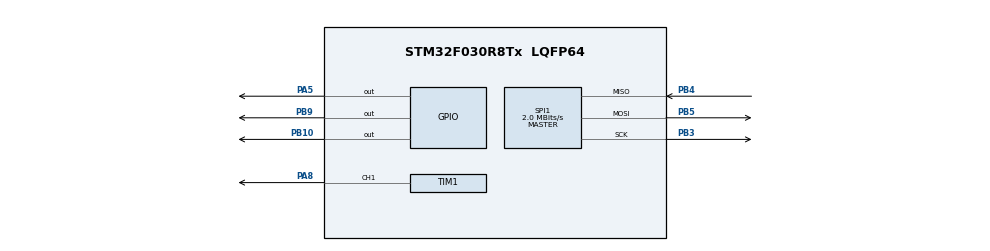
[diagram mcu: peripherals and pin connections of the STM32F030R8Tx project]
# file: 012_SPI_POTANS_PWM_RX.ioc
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Mcu.Family=STM32F0
Mcu.Name=STM32F030R8Tx
Mcu.Package=LQFP64
PA13.Mode=Serial_Wire
PA13.Signal=SYS_SWDIO
PA14.Mode=Serial_Wire
PA14.Signal=SYS_SWCLK
PA5.Signal=GPIO_Output
PA8.Signal=S_TIM1_CH1
PB10.GPIO_Speed=GPIO_SPEED_FREQ_HIGH
PB10.PinState=GPIO_PIN_RESET
PB10.Signal=GPIO_Output
PB3.Mode=Full_Duplex_Master
PB3.Signal=SPI1_SCK
PB4.Mode=Full_Duplex_Master
PB4.Signal=SPI1_MISO
PB5.Mode=Full_Duplex_Master
PB5.Signal=SPI1_MOSI
PB9.GPIO_Speed=GPIO_SPEED_FREQ_HIGH
PB9.Signal=GPIO_Output
ProjectManager.HeapSize=0x200
ProjectManager.StackSize=0x400
ProjectManager.TargetToolchain=STM32CubeIDE
SH.S_TIM1_CH1.0=TIM1_CH1,PWM Generation1 CH1
SPI1.BaudRatePrescaler=SPI_BAUDRATEPRESCALER_4
SPI1.CalculateBaudRate=2.0 MBits/s
SPI1.DataSize=SPI_DATASIZE_8BIT
SPI1.Direction=SPI_DIRECTION_2LINES
SPI1.Mode=SPI_MODE_MASTER
SPI1.VirtualType=VM_MASTER
TIM1.Channel-PWM\ Generation1\ CH1=TIM_CHANNEL_1
TIM1.Period=255
TIM1.Prescaler=8-1
VP_TIM1_VS_ClockSourceINT.Mode=Internal
board=custom

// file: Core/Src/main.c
/* USER CODE BEGIN Header */
/**
  ******************************************************************************
  * @file           : main.c
  * @brief          : Main program body
  ******************************************************************************
  * @attention
  *
  * Copyright (c) 2025 STMicroelectronics.
  * All rights reserved.
  *
  * This software is licensed under terms that can be found in the LICENSE file
  * in the root directory of this software component.
  * If no LICENSE file comes with this software, it is provided AS-IS.
  *
  ******************************************************************************
  */
/* USER CODE END Header */
#include "main.h"

/* USER CODE BEGIN Includes */
#include "nrf24l01.h"
#include "string.h"

/* USER CODE END Includes */

SPI_HandleTypeDef hspi1;

TIM_HandleTypeDef htim1;

/* USER CODE BEGIN PV */
uint8_t rx_address[5] = {0xD1, 0xC2, 0xC3, 0xC4, 0xC5}; // Özel bir adres
uint8_t rx_data[1]; // Gelen veri icin buffer
/* USER CODE END PV */

void SystemClock_Config(void);
static void MX_GPIO_Init(void);
static void MX_SPI1_Init(void);
static void MX_TIM1_Init(void);

int main(void)
{

  /* MCU Configuration--------------------------------------------------------*/

  /* Reset of all peripherals, Initializes the Flash interface and the Systick. */
  HAL_Init();

  /* Configure the system clock */
  SystemClock_Config();

  /* Initialize all configured peripherals */
  MX_GPIO_Init();
  MX_SPI1_Init();
  MX_TIM1_Init();
  /* USER CODE BEGIN 2 */
  	  nrf24_config(40, 1);
      nrf24_rx_address(rx_address);
      nrf24_rx_mode();
      HAL_TIM_PWM_Start(&htim1, TIM_CHANNEL_1);
  /* USER CODE END 2 */

  /* Infinite loop */
  while (1)
  {

    /* USER CODE BEGIN 3 */

	   if (nrf24_dataReady()) // Veri var mı?
	        {
	            nrf24_getData((uint8_t*)rx_data, 1); // Gelen veriyi al
	            __HAL_TIM_SET_COMPARE(&htim1, TIM_CHANNEL_1, rx_data[0]);
	            HAL_GPIO_TogglePin(GPIOA, GPIO_PIN_5);
	             HAL_Delay(50);
	        }
  }
  /* USER CODE END 3 */
}

void SystemClock_Config(void)
{
  RCC_OscInitTypeDef RCC_OscInitStruct = {0};
  RCC_ClkInitTypeDef RCC_ClkInitStruct = {0};

  /** Initializes the RCC Oscillators according to the specified parameters
  * in the RCC_OscInitTypeDef structure.
  */
  RCC_OscInitStruct.OscillatorType = RCC_OSCILLATORTYPE_HSI;
  RCC_OscInitStruct.HSIState = RCC_HSI_ON;
  RCC_OscInitStruct.HSICalibrationValue = RCC_HSICALIBRATION_DEFAULT;
  RCC_OscInitStruct.PLL.PLLState = RCC_PLL_NONE;
  if (HAL_RCC_OscConfig(&RCC_OscInitStruct) != HAL_OK)
  {
    Error_Handler();
  }

  /** Initializes the CPU, AHB and APB buses clocks
  */
  RCC_ClkInitStruct.ClockType = RCC_CLOCKTYPE_HCLK|RCC_CLOCKTYPE_SYSCLK
                              |RCC_CLOCKTYPE_PCLK1;
  RCC_ClkInitStruct.SYSCLKSource = RCC_SYSCLKSOURCE_HSI;
  RCC_ClkInitStruct.AHBCLKDivider = RCC_SYSCLK_DIV1;
  RCC_ClkInitStruct.APB1CLKDivider = RCC_HCLK_DIV1;

  if (HAL_RCC_ClockConfig(&RCC_ClkInitStruct, FLASH_LATENCY_0) != HAL_OK)
  {
    Error_Handler();
  }
}

static void MX_SPI1_Init(void)
{

  /* SPI1 parameter configuration*/
  hspi1.Instance = SPI1;
  hspi1.Init.Mode = SPI_MODE_MASTER;
  hspi1.Init.Direction = SPI_DIRECTION_2LINES;
  hspi1.Init.DataSize = SPI_DATASIZE_8BIT;
  hspi1.Init.CLKPolarity = SPI_POLARITY_LOW;
  hspi1.Init.CLKPhase = SPI_PHASE_1EDGE;
  hspi1.Init.NSS = SPI_NSS_SOFT;
  hspi1.Init.BaudRatePrescaler = SPI_BAUDRATEPRESCALER_4;
  hspi1.Init.FirstBit = SPI_FIRSTBIT_MSB;
  hspi1.Init.TIMode = SPI_TIMODE_DISABLE;
  hspi1.Init.CRCCalculation = SPI_CRCCALCULATION_DISABLE;
  hspi1.Init.CRCPolynomial = 7;
  hspi1.Init.CRCLength = SPI_CRC_LENGTH_DATASIZE;
  hspi1.Init.NSSPMode = SPI_NSS_PULSE_ENABLE;
  if (HAL_SPI_Init(&hspi1) != HAL_OK)
  {
    Error_Handler();
  }

}

static void MX_TIM1_Init(void)
{

  TIM_ClockConfigTypeDef sClockSourceConfig = {0};
  TIM_MasterConfigTypeDef sMasterConfig = {0};
  TIM_OC_InitTypeDef sConfigOC = {0};
  TIM_BreakDeadTimeConfigTypeDef sBreakDeadTimeConfig = {0};

  htim1.Instance = TIM1;
  htim1.Init.Prescaler = 8-1;
  htim1.Init.CounterMode = TIM_COUNTERMODE_UP;
  htim1.Init.Period = 255;
  htim1.Init.ClockDivision = TIM_CLOCKDIVISION_DIV1;
  htim1.Init.RepetitionCounter = 0;
  htim1.Init.AutoReloadPreload = TIM_AUTORELOAD_PRELOAD_DISABLE;
  if (HAL_TIM_Base_Init(&htim1) != HAL_OK)
  {
    Error_Handler();
  }
  sClockSourceConfig.ClockSource = TIM_CLOCKSOURCE_INTERNAL;
  if (HAL_TIM_ConfigClockSource(&htim1, &sClockSourceConfig) != HAL_OK)
  {
    Error_Handler();
  }
  if (HAL_TIM_PWM_Init(&htim1) != HAL_OK)
  {
    Error_Handler();
  }
  sMasterConfig.MasterOutputTrigger = TIM_TRGO_RESET;
  sMasterConfig.MasterSlaveMode = TIM_MASTERSLAVEMODE_DISABLE;
  if (HAL_TIMEx_MasterConfigSynchronization(&htim1, &sMasterConfig) != HAL_OK)
  {
    Error_Handler();
  }
  sConfigOC.OCMode = TIM_OCMODE_PWM1;
  sConfigOC.Pulse = 0;
  sConfigOC.OCPolarity = TIM_OCPOLARITY_HIGH;
  sConfigOC.OCNPolarity = TIM_OCNPOLARITY_HIGH;
  sConfigOC.OCFastMode = TIM_OCFAST_DISABLE;
  sConfigOC.OCIdleState = TIM_OCIDLESTATE_RESET;
  sConfigOC.OCNIdleState = TIM_OCNIDLESTATE_RESET;
  if (HAL_TIM_PWM_ConfigChannel(&htim1, &sConfigOC, TIM_CHANNEL_1) != HAL_OK)
  {
    Error_Handler();
  }
  sBreakDeadTimeConfig.OffStateRunMode = TIM_OSSR_DISABLE;
  sBreakDeadTimeConfig.OffStateIDLEMode = TIM_OSSI_DISABLE;
  sBreakDeadTimeConfig.LockLevel = TIM_LOCKLEVEL_OFF;
  sBreakDeadTimeConfig.DeadTime = 0;
  sBreakDeadTimeConfig.BreakState = TIM_BREAK_DISABLE;
  sBreakDeadTimeConfig.BreakPolarity = TIM_BREAKPOLARITY_HIGH;
  sBreakDeadTimeConfig.AutomaticOutput = TIM_AUTOMATICOUTPUT_DISABLE;
  if (HAL_TIMEx_ConfigBreakDeadTime(&htim1, &sBreakDeadTimeConfig) != HAL_OK)
  {
    Error_Handler();
  }
  HAL_TIM_MspPostInit(&htim1);

}

static void MX_GPIO_Init(void)
{
  GPIO_InitTypeDef GPIO_InitStruct = {0};

  /* GPIO Ports Clock Enable */
  __HAL_RCC_GPIOA_CLK_ENABLE();
  __HAL_RCC_GPIOB_CLK_ENABLE();

  /*Configure GPIO pin Output Level */
  HAL_GPIO_WritePin(GPIOA, GPIO_PIN_5, GPIO_PIN_RESET);

  /*Configure GPIO pin Output Level */
  HAL_GPIO_WritePin(GPIOB, GPIO_PIN_10|GPIO_PIN_9, GPIO_PIN_RESET);

  /*Configure GPIO pin : PA5 */
  GPIO_InitStruct.Pin = GPIO_PIN_5;
  GPIO_InitStruct.Mode = GPIO_MODE_OUTPUT_PP;
  GPIO_InitStruct.Pull = GPIO_NOPULL;
  GPIO_InitStruct.Speed = GPIO_SPEED_FREQ_LOW;
  HAL_GPIO_Init(GPIOA, &GPIO_InitStruct);

  /*Configure GPIO pins : PB10 PB9 */
  GPIO_InitStruct.Pin = GPIO_PIN_10|GPIO_PIN_9;
  GPIO_InitStruct.Mode = GPIO_MODE_OUTPUT_PP;
  GPIO_InitStruct.Pull = GPIO_NOPULL;
  GPIO_InitStruct.Speed = GPIO_SPEED_FREQ_HIGH;
  HAL_GPIO_Init(GPIOB, &GPIO_InitStruct);

}

void Error_Handler(void)
{
  __disable_irq();
  while (1)
  {
  }
}
